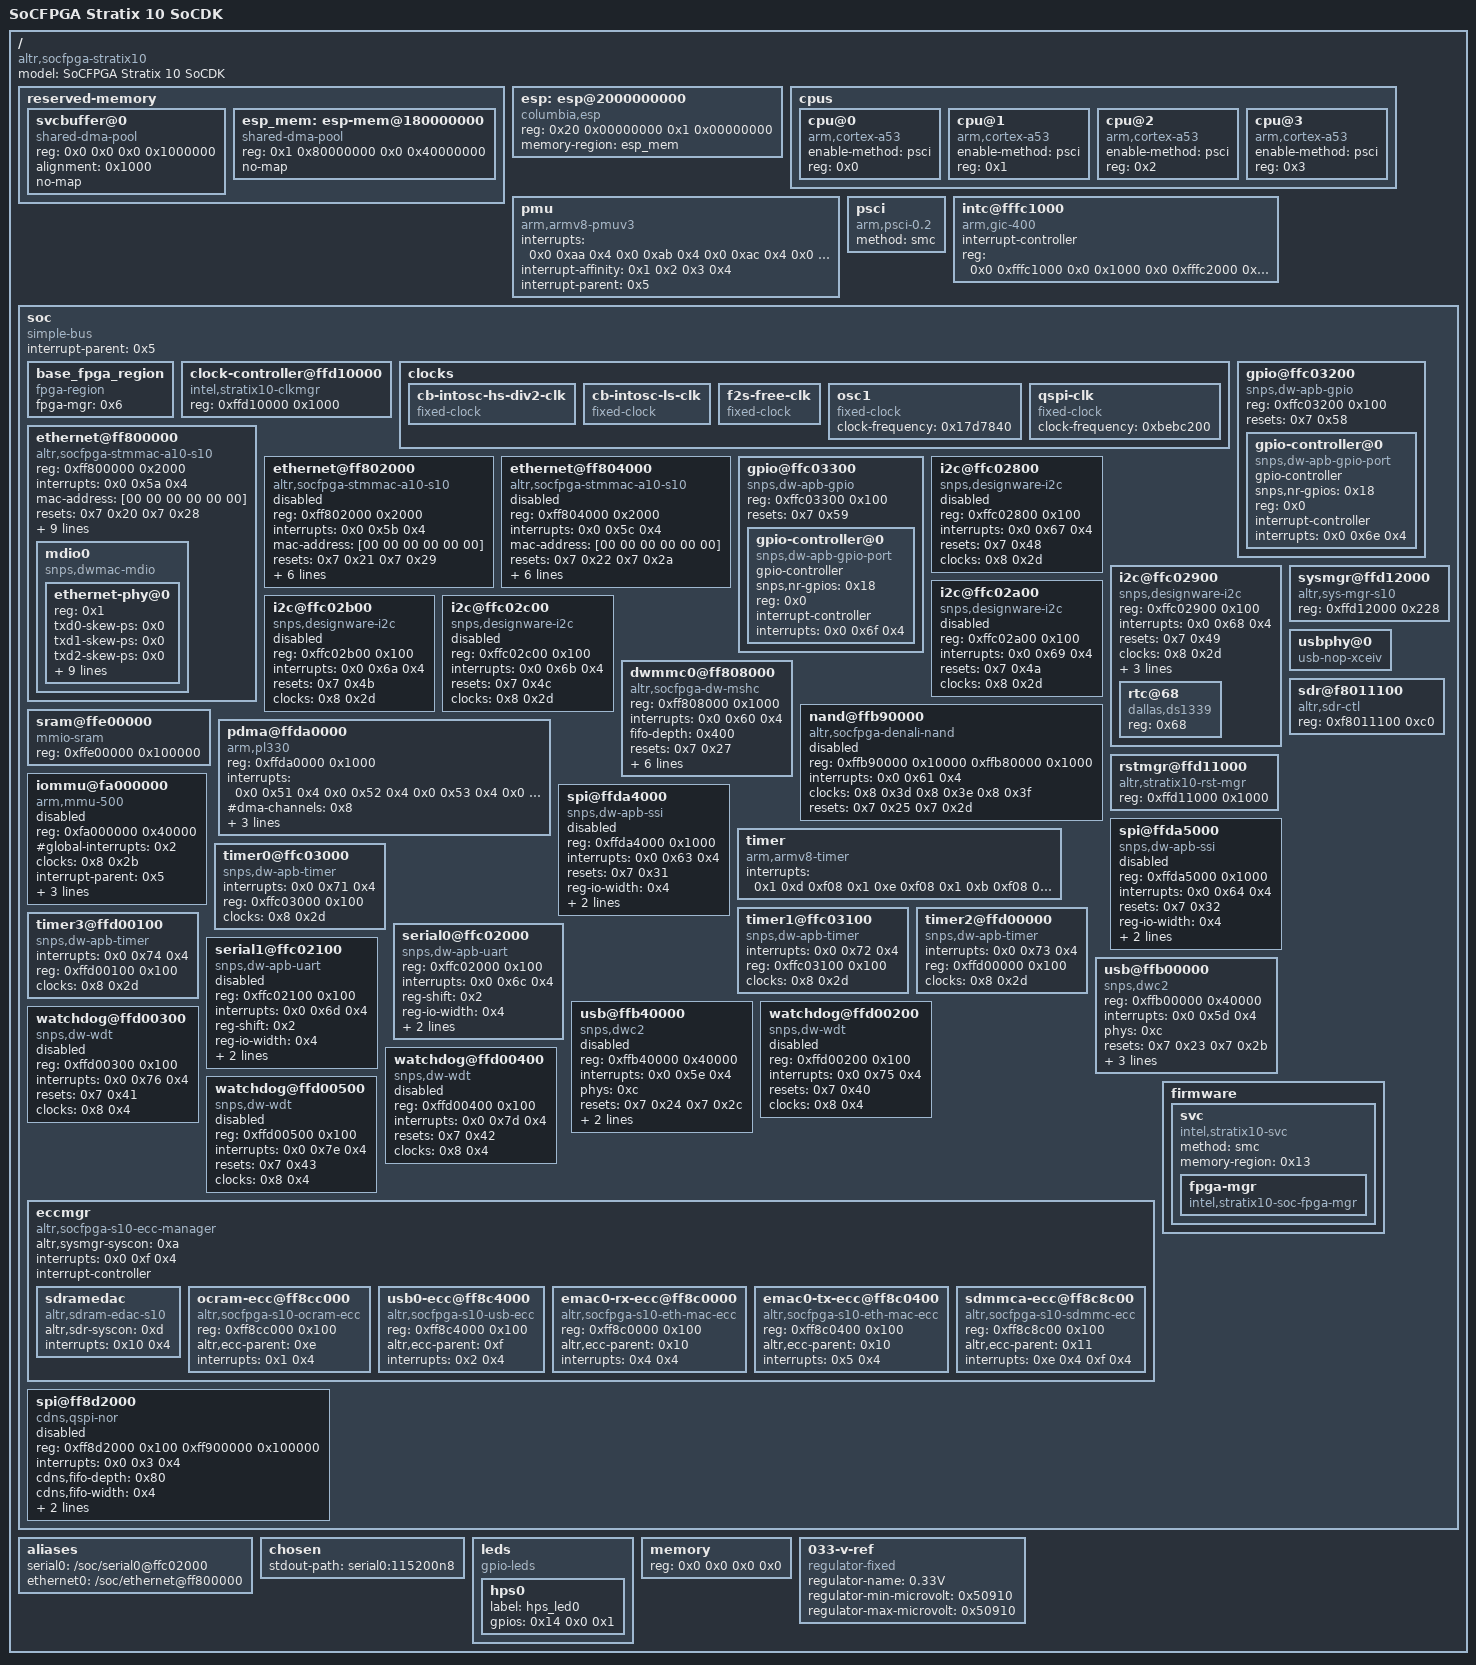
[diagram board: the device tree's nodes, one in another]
/dts-v1/;

/ {
	compatible = "altr,socfpga-stratix10";
	#address-cells = <0x2>;
	#size-cells = <0x2>;
	model = "SoCFPGA Stratix 10 SoCDK";

	reserved-memory {
		#address-cells = <0x2>;
		#size-cells = <0x2>;
		ranges;

		svcbuffer@0 {
			compatible = "shared-dma-pool";
			reg = <0x0 0x0 0x0 0x1000000>;
			alignment = <0x1000>;
			no-map;
			phandle = <0x13>;
		};

		esp_mem: esp-mem@180000000 {
			compatible = "shared-dma-pool";
			reg = <0x1 0x80000000 0x0 0x40000000>; /* 1GB at CPU physical 0x1_8000_0000, matching ESP DRAM aperture */
			no-map;
		};
	};

	esp: esp@2000000000 {
		compatible = "columbia,esp";
		#address-cells = <2>;
		#size-cells = <2>;
		ranges;

		/* Full 4GB H2F MMIO window: 0x20_0000_0000 .. 0x20_FFFF_FFFF */
		reg = <0x20 0x00000000 0x1 0x00000000>;

		memory-region = <&esp_mem>;

		/*
		 * Optional subnodes can mirror the Zynq devicetree if the ESP
		 * driver needs per-region children later.
		 */
	};

	cpus {
		#address-cells = <0x1>;
		#size-cells = <0x0>;

		cpu@0 {
			compatible = "arm,cortex-a53";
			device_type = "cpu";
			enable-method = "psci";
			reg = <0x0>;
			phandle = <0x1>;
		};

		cpu@1 {
			compatible = "arm,cortex-a53";
			device_type = "cpu";
			enable-method = "psci";
			reg = <0x1>;
			phandle = <0x2>;
		};

		cpu@2 {
			compatible = "arm,cortex-a53";
			device_type = "cpu";
			enable-method = "psci";
			reg = <0x2>;
			phandle = <0x3>;
		};

		cpu@3 {
			compatible = "arm,cortex-a53";
			device_type = "cpu";
			enable-method = "psci";
			reg = <0x3>;
			phandle = <0x4>;
		};
	};

	pmu {
		compatible = "arm,armv8-pmuv3";
		interrupts = <0x0 0xaa 0x4 0x0 0xab 0x4 0x0 0xac 0x4 0x0 0xad 0x4>;
		interrupt-affinity = <0x1 0x2 0x3 0x4>;
		interrupt-parent = <0x5>;
	};

	psci {
		compatible = "arm,psci-0.2";
		method = "smc";
	};

	intc@fffc1000 {
		compatible = "arm,gic-400", "arm,cortex-a15-gic";
		#interrupt-cells = <0x3>;
		interrupt-controller;
		reg = <0x0 0xfffc1000 0x0 0x1000 0x0 0xfffc2000 0x0 0x2000 0x0 0xfffc4000 0x0 0x2000 0x0 0xfffc6000 0x0 0x2000>;
		phandle = <0x5>;
	};

	soc {
		#address-cells = <0x1>;
		#size-cells = <0x1>;
		compatible = "simple-bus";
		device_type = "soc";
		interrupt-parent = <0x5>;
		ranges = <0x0 0x0 0x0 0xffffffff>;

		base_fpga_region {
			#address-cells = <0x1>;
			#size-cells = <0x1>;
			compatible = "fpga-region";
			fpga-mgr = <0x6>;
		};

		clock-controller@ffd10000 {
			compatible = "intel,stratix10-clkmgr";
			reg = <0xffd10000 0x1000>;
			#clock-cells = <0x1>;
			phandle = <0x8>;
		};

		clocks {

			cb-intosc-hs-div2-clk {
				#clock-cells = <0x0>;
				compatible = "fixed-clock";
				phandle = <0x15>;
			};

			cb-intosc-ls-clk {
				#clock-cells = <0x0>;
				compatible = "fixed-clock";
				phandle = <0x16>;
			};

			f2s-free-clk {
				#clock-cells = <0x0>;
				compatible = "fixed-clock";
				phandle = <0x17>;
			};

			osc1 {
				#clock-cells = <0x0>;
				compatible = "fixed-clock";
				clock-frequency = <0x17d7840>;
				phandle = <0x18>;
			};

			qspi-clk {
				#clock-cells = <0x0>;
				compatible = "fixed-clock";
				clock-frequency = <0xbebc200>;
				phandle = <0x12>;
			};
		};

		ethernet@ff800000 {
			compatible = "altr,socfpga-stmmac-a10-s10", "snps,dwmac-3.74a", "snps,dwmac";
			reg = <0xff800000 0x2000>;
			interrupts = <0x0 0x5a 0x4>;
			interrupt-names = "macirq";
			mac-address = [00 00 00 00 00 00];
			resets = <0x7 0x20 0x7 0x28>;
			reset-names = "stmmaceth", "stmmaceth-ocp";
			clocks = <0x8 0x34>;
			clock-names = "stmmaceth";
			tx-fifo-depth = <0x4000>;
			rx-fifo-depth = <0x4000>;
			snps,multicast-filter-bins = <0x100>;
			iommus = <0x9 0x1>;
			altr,sysmgr-syscon = <0xa 0x44 0x0>;
			status = "okay";
			phy-mode = "rgmii";
			phy-handle = <0xb>;
			max-frame-size = <0x2328>;
			phandle = <0x10>;

			mdio0 {
				#address-cells = <0x1>;
				#size-cells = <0x0>;
				compatible = "snps,dwmac-mdio";

				ethernet-phy@0 {
					reg = <0x1>;
					txd0-skew-ps = <0x0>;
					txd1-skew-ps = <0x0>;
					txd2-skew-ps = <0x0>;
					txd3-skew-ps = <0x0>;
					rxd0-skew-ps = <0x1a4>;
					rxd1-skew-ps = <0x1a4>;
					rxd2-skew-ps = <0x1a4>;
					rxd3-skew-ps = <0x1a4>;
					txen-skew-ps = <0x0>;
					txc-skew-ps = <0x384>;
					rxdv-skew-ps = <0x1a4>;
					rxc-skew-ps = <0x690>;
					phandle = <0xb>;
				};
			};
		};

		ethernet@ff802000 {
			compatible = "altr,socfpga-stmmac-a10-s10", "snps,dwmac-3.74a", "snps,dwmac";
			reg = <0xff802000 0x2000>;
			interrupts = <0x0 0x5b 0x4>;
			interrupt-names = "macirq";
			mac-address = [00 00 00 00 00 00];
			resets = <0x7 0x21 0x7 0x29>;
			reset-names = "stmmaceth", "stmmaceth-ocp";
			clocks = <0x8 0x35>;
			clock-names = "stmmaceth";
			tx-fifo-depth = <0x4000>;
			rx-fifo-depth = <0x4000>;
			snps,multicast-filter-bins = <0x100>;
			iommus = <0x9 0x2>;
			altr,sysmgr-syscon = <0xa 0x48 0x8>;
			status = "disabled";
			phandle = <0x19>;
		};

		ethernet@ff804000 {
			compatible = "altr,socfpga-stmmac-a10-s10", "snps,dwmac-3.74a", "snps,dwmac";
			reg = <0xff804000 0x2000>;
			interrupts = <0x0 0x5c 0x4>;
			interrupt-names = "macirq";
			mac-address = [00 00 00 00 00 00];
			resets = <0x7 0x22 0x7 0x2a>;
			reset-names = "stmmaceth", "stmmaceth-ocp";
			clocks = <0x8 0x36>;
			clock-names = "stmmaceth";
			tx-fifo-depth = <0x4000>;
			rx-fifo-depth = <0x4000>;
			snps,multicast-filter-bins = <0x100>;
			iommus = <0x9 0x3>;
			altr,sysmgr-syscon = <0xa 0x4c 0x10>;
			status = "disabled";
			phandle = <0x1a>;
		};

		gpio@ffc03200 {
			#address-cells = <0x1>;
			#size-cells = <0x0>;
			compatible = "snps,dw-apb-gpio";
			reg = <0xffc03200 0x100>;
			resets = <0x7 0x58>;
			status = "okay";
			phandle = <0x1b>;

			gpio-controller@0 {
				compatible = "snps,dw-apb-gpio-port";
				gpio-controller;
				#gpio-cells = <0x2>;
				snps,nr-gpios = <0x18>;
				reg = <0x0>;
				interrupt-controller;
				#interrupt-cells = <0x2>;
				interrupts = <0x0 0x6e 0x4>;
				phandle = <0x1c>;
			};
		};

		gpio@ffc03300 {
			#address-cells = <0x1>;
			#size-cells = <0x0>;
			compatible = "snps,dw-apb-gpio";
			reg = <0xffc03300 0x100>;
			resets = <0x7 0x59>;
			status = "okay";
			phandle = <0x1d>;

			gpio-controller@0 {
				compatible = "snps,dw-apb-gpio-port";
				gpio-controller;
				#gpio-cells = <0x2>;
				snps,nr-gpios = <0x18>;
				reg = <0x0>;
				interrupt-controller;
				#interrupt-cells = <0x2>;
				interrupts = <0x0 0x6f 0x4>;
				phandle = <0x14>;
			};
		};

		i2c@ffc02800 {
			#address-cells = <0x1>;
			#size-cells = <0x0>;
			compatible = "snps,designware-i2c";
			reg = <0xffc02800 0x100>;
			interrupts = <0x0 0x67 0x4>;
			resets = <0x7 0x48>;
			clocks = <0x8 0x2d>;
			status = "disabled";
			phandle = <0x1e>;
		};

		i2c@ffc02900 {
			#address-cells = <0x1>;
			#size-cells = <0x0>;
			compatible = "snps,designware-i2c";
			reg = <0xffc02900 0x100>;
			interrupts = <0x0 0x68 0x4>;
			resets = <0x7 0x49>;
			clocks = <0x8 0x2d>;
			status = "okay";
			clock-frequency = <0x186a0>;
			i2c-sda-falling-time-ns = <0x37a>;
			i2c-sdl-falling-time-ns = <0x37a>;
			phandle = <0x1f>;

			rtc@68 {
				compatible = "dallas,ds1339";
				reg = <0x68>;
			};
		};

		i2c@ffc02a00 {
			#address-cells = <0x1>;
			#size-cells = <0x0>;
			compatible = "snps,designware-i2c";
			reg = <0xffc02a00 0x100>;
			interrupts = <0x0 0x69 0x4>;
			resets = <0x7 0x4a>;
			clocks = <0x8 0x2d>;
			status = "disabled";
			phandle = <0x20>;
		};

		i2c@ffc02b00 {
			#address-cells = <0x1>;
			#size-cells = <0x0>;
			compatible = "snps,designware-i2c";
			reg = <0xffc02b00 0x100>;
			interrupts = <0x0 0x6a 0x4>;
			resets = <0x7 0x4b>;
			clocks = <0x8 0x2d>;
			status = "disabled";
			phandle = <0x21>;
		};

		i2c@ffc02c00 {
			#address-cells = <0x1>;
			#size-cells = <0x0>;
			compatible = "snps,designware-i2c";
			reg = <0xffc02c00 0x100>;
			interrupts = <0x0 0x6b 0x4>;
			resets = <0x7 0x4c>;
			clocks = <0x8 0x2d>;
			status = "disabled";
			phandle = <0x22>;
		};

		dwmmc0@ff808000 {
			#address-cells = <0x1>;
			#size-cells = <0x0>;
			compatible = "altr,socfpga-dw-mshc";
			reg = <0xff808000 0x1000>;
			interrupts = <0x0 0x60 0x4>;
			fifo-depth = <0x400>;
			resets = <0x7 0x27>;
			reset-names = "reset";
			clocks = <0x8 0x2c 0x8 0x39>;
			clock-names = "biu", "ciu";
			iommus = <0x9 0x5>;
			status = "okay";
			cap-sd-highspeed;
			cap-mmc-highspeed;
			broken-cd;
			bus-width = <0x4>;
			phandle = <0x11>;
		};

		nand@ffb90000 {
			#address-cells = <0x1>;
			#size-cells = <0x0>;
			compatible = "altr,socfpga-denali-nand";
			reg = <0xffb90000 0x10000 0xffb80000 0x1000>;
			reg-names = "nand_data", "denali_reg";
			interrupts = <0x0 0x61 0x4>;
			clocks = <0x8 0x3d 0x8 0x3e 0x8 0x3f>;
			clock-names = "nand", "nand_x", "ecc";
			resets = <0x7 0x25 0x7 0x2d>;
			status = "disabled";
			phandle = <0x23>;
		};

		sram@ffe00000 {
			compatible = "mmio-sram";
			reg = <0xffe00000 0x100000>;
			phandle = <0xe>;
		};

		pdma@ffda0000 {
			compatible = "arm,pl330", "arm,primecell";
			reg = <0xffda0000 0x1000>;
			interrupts = <0x0 0x51 0x4 0x0 0x52 0x4 0x0 0x53 0x4 0x0 0x54 0x4 0x0 0x55 0x4 0x0 0x56 0x4 0x0 0x57 0x4 0x0 0x58 0x4 0x0 0x59 0x4>;
			#dma-cells = <0x1>;
			#dma-channels = <0x8>;
			#dma-requests = <0x20>;
			clocks = <0x8 0x2b>;
			clock-names = "apb_pclk";
			resets = <0x7 0x30 0x7 0x35>;
			reset-names = "dma", "dma-ocp";
			phandle = <0x24>;
		};

		rstmgr@ffd11000 {
			#reset-cells = <0x1>;
			compatible = "altr,stratix10-rst-mgr";
			reg = <0xffd11000 0x1000>;
			phandle = <0x7>;
		};

		iommu@fa000000 {
			compatible = "arm,mmu-500", "arm,smmu-v2";
			reg = <0xfa000000 0x40000>;
			#global-interrupts = <0x2>;
			#iommu-cells = <0x1>;
			clocks = <0x8 0x2b>;
			clock-names = "iommu";
			interrupt-parent = <0x5>;
			interrupts = <0x0 0x80 0x4 0x0 0x81 0x4 0x0 0x8a 0x4 0x0 0x8b 0x4 0x0 0x8c 0x4 0x0 0x8d 0x4 0x0 0x8e 0x4 0x0 0x8f 0x4 0x0 0x90 0x4 0x0 0x91 0x4 0x0 0x92 0x4 0x0 0x93 0x4 0x0 0x94 0x4 0x0 0x95 0x4 0x0 0x96 0x4 0x0 0x97 0x4 0x0 0x98 0x4 0x0 0x99 0x4 0x0 0x9a 0x4 0x0 0x9b 0x4 0x0 0x9c 0x4 0x0 0x9d 0x4 0x0 0x9e 0x4 0x0 0x9f 0x4 0x0 0xa0 0x4 0x0 0xa1 0x4 0x0 0xa2 0x4 0x0 0xa3 0x4 0x0 0xa4 0x4 0x0 0xa5 0x4 0x0 0xa6 0x4 0x0 0xa7 0x4 0x0 0xa8 0x4 0x0 0xa9 0x4>;
			stream-match-mask = <0x7ff0>;
			status = "disabled";
			phandle = <0x9>;
		};

		spi@ffda4000 {
			compatible = "snps,dw-apb-ssi";
			#address-cells = <0x1>;
			#size-cells = <0x0>;
			reg = <0xffda4000 0x1000>;
			interrupts = <0x0 0x63 0x4>;
			resets = <0x7 0x31>;
			reg-io-width = <0x4>;
			num-cs = <0x4>;
			clocks = <0x8 0x2b>;
			status = "disabled";
			phandle = <0x25>;
		};

		spi@ffda5000 {
			compatible = "snps,dw-apb-ssi";
			#address-cells = <0x1>;
			#size-cells = <0x0>;
			reg = <0xffda5000 0x1000>;
			interrupts = <0x0 0x64 0x4>;
			resets = <0x7 0x32>;
			reg-io-width = <0x4>;
			num-cs = <0x4>;
			clocks = <0x8 0x2b>;
			status = "disabled";
			phandle = <0x26>;
		};

		sysmgr@ffd12000 {
			compatible = "altr,sys-mgr-s10", "altr,sys-mgr";
			reg = <0xffd12000 0x228>;
			phandle = <0xa>;
		};

		timer {
			compatible = "arm,armv8-timer";
			interrupts = <0x1 0xd 0xf08 0x1 0xe 0xf08 0x1 0xb 0xf08 0x1 0xa 0xf08>;
		};

		timer0@ffc03000 {
			compatible = "snps,dw-apb-timer";
			interrupts = <0x0 0x71 0x4>;
			reg = <0xffc03000 0x100>;
			clocks = <0x8 0x2d>;
			clock-names = "timer";
			phandle = <0x27>;
		};

		timer1@ffc03100 {
			compatible = "snps,dw-apb-timer";
			interrupts = <0x0 0x72 0x4>;
			reg = <0xffc03100 0x100>;
			clocks = <0x8 0x2d>;
			clock-names = "timer";
			phandle = <0x28>;
		};

		timer2@ffd00000 {
			compatible = "snps,dw-apb-timer";
			interrupts = <0x0 0x73 0x4>;
			reg = <0xffd00000 0x100>;
			clocks = <0x8 0x2d>;
			clock-names = "timer";
			phandle = <0x29>;
		};

		timer3@ffd00100 {
			compatible = "snps,dw-apb-timer";
			interrupts = <0x0 0x74 0x4>;
			reg = <0xffd00100 0x100>;
			clocks = <0x8 0x2d>;
			clock-names = "timer";
			phandle = <0x2a>;
		};

		serial0@ffc02000 {
			compatible = "snps,dw-apb-uart";
			reg = <0xffc02000 0x100>;
			interrupts = <0x0 0x6c 0x4>;
			reg-shift = <0x2>;
			reg-io-width = <0x4>;
			resets = <0x7 0x50>;
			clocks = <0x8 0x2d>;
			status = "okay";
			phandle = <0x2b>;
		};

		serial1@ffc02100 {
			compatible = "snps,dw-apb-uart";
			reg = <0xffc02100 0x100>;
			interrupts = <0x0 0x6d 0x4>;
			reg-shift = <0x2>;
			reg-io-width = <0x4>;
			resets = <0x7 0x51>;
			clocks = <0x8 0x2d>;
			status = "disabled";
			phandle = <0x2c>;
		};

		usbphy@0 {
			#phy-cells = <0x0>;
			compatible = "usb-nop-xceiv";
			status = "okay";
			phandle = <0xc>;
		};

		usb@ffb00000 {
			compatible = "snps,dwc2";
			reg = <0xffb00000 0x40000>;
			interrupts = <0x0 0x5d 0x4>;
			phys = <0xc>;
			phy-names = "usb2-phy";
			resets = <0x7 0x23 0x7 0x2b>;
			reset-names = "dwc2", "dwc2-ecc";
			clocks = <0x8 0x3b>;
			iommus = <0x9 0x6>;
			status = "okay";
			disable-over-current;
			phandle = <0xf>;
		};

		usb@ffb40000 {
			compatible = "snps,dwc2";
			reg = <0xffb40000 0x40000>;
			interrupts = <0x0 0x5e 0x4>;
			phys = <0xc>;
			phy-names = "usb2-phy";
			resets = <0x7 0x24 0x7 0x2c>;
			reset-names = "dwc2", "dwc2-ecc";
			clocks = <0x8 0x3b>;
			iommus = <0x9 0x7>;
			status = "disabled";
			phandle = <0x2d>;
		};

		watchdog@ffd00200 {
			compatible = "snps,dw-wdt";
			reg = <0xffd00200 0x100>;
			interrupts = <0x0 0x75 0x4>;
			resets = <0x7 0x40>;
			clocks = <0x8 0x4>;
			status = "disabled";
			phandle = <0x2e>;
		};

		watchdog@ffd00300 {
			compatible = "snps,dw-wdt";
			reg = <0xffd00300 0x100>;
			interrupts = <0x0 0x76 0x4>;
			resets = <0x7 0x41>;
			clocks = <0x8 0x4>;
			status = "disabled";
			phandle = <0x2f>;
		};

		watchdog@ffd00400 {
			compatible = "snps,dw-wdt";
			reg = <0xffd00400 0x100>;
			interrupts = <0x0 0x7d 0x4>;
			resets = <0x7 0x42>;
			clocks = <0x8 0x4>;
			status = "disabled";
			phandle = <0x30>;
		};

		watchdog@ffd00500 {
			compatible = "snps,dw-wdt";
			reg = <0xffd00500 0x100>;
			interrupts = <0x0 0x7e 0x4>;
			resets = <0x7 0x43>;
			clocks = <0x8 0x4>;
			status = "disabled";
			phandle = <0x31>;
		};

		sdr@f8011100 {
			compatible = "altr,sdr-ctl", "syscon";
			reg = <0xf8011100 0xc0>;
			phandle = <0xd>;
		};

		eccmgr {
			compatible = "altr,socfpga-s10-ecc-manager", "altr,socfpga-a10-ecc-manager";
			altr,sysmgr-syscon = <0xa>;
			#address-cells = <0x1>;
			#size-cells = <0x1>;
			interrupts = <0x0 0xf 0x4>;
			interrupt-controller;
			#interrupt-cells = <0x2>;
			ranges;

			sdramedac {
				compatible = "altr,sdram-edac-s10";
				altr,sdr-syscon = <0xd>;
				interrupts = <0x10 0x4>;
			};

			ocram-ecc@ff8cc000 {
				compatible = "altr,socfpga-s10-ocram-ecc", "altr,socfpga-a10-ocram-ecc";
				reg = <0xff8cc000 0x100>;
				altr,ecc-parent = <0xe>;
				interrupts = <0x1 0x4>;
			};

			usb0-ecc@ff8c4000 {
				compatible = "altr,socfpga-s10-usb-ecc", "altr,socfpga-usb-ecc";
				reg = <0xff8c4000 0x100>;
				altr,ecc-parent = <0xf>;
				interrupts = <0x2 0x4>;
			};

			emac0-rx-ecc@ff8c0000 {
				compatible = "altr,socfpga-s10-eth-mac-ecc", "altr,socfpga-eth-mac-ecc";
				reg = <0xff8c0000 0x100>;
				altr,ecc-parent = <0x10>;
				interrupts = <0x4 0x4>;
			};

			emac0-tx-ecc@ff8c0400 {
				compatible = "altr,socfpga-s10-eth-mac-ecc", "altr,socfpga-eth-mac-ecc";
				reg = <0xff8c0400 0x100>;
				altr,ecc-parent = <0x10>;
				interrupts = <0x5 0x4>;
			};

			sdmmca-ecc@ff8c8c00 {
				compatible = "altr,socfpga-s10-sdmmc-ecc", "altr,socfpga-sdmmc-ecc";
				reg = <0xff8c8c00 0x100>;
				altr,ecc-parent = <0x11>;
				interrupts = <0xe 0x4 0xf 0x4>;
			};
		};

		spi@ff8d2000 {
			compatible = "cdns,qspi-nor";
			#address-cells = <0x1>;
			#size-cells = <0x0>;
			reg = <0xff8d2000 0x100 0xff900000 0x100000>;
			interrupts = <0x0 0x3 0x4>;
			cdns,fifo-depth = <0x80>;
			cdns,fifo-width = <0x4>;
			cdns,trigger-address = <0x0>;
			clocks = <0x12>;
			status = "disabled";
			phandle = <0x32>;
		};

		firmware {

			svc {
				compatible = "intel,stratix10-svc";
				method = "smc";
				memory-region = <0x13>;

				fpga-mgr {
					compatible = "intel,stratix10-soc-fpga-mgr";
					phandle = <0x6>;
				};
			};
		};
	};

	aliases {
		serial0 = "/soc/serial0@ffc02000";
		ethernet0 = "/soc/ethernet@ff800000";
	};

	chosen {
		stdout-path = "serial0:115200n8";
	};

	leds {
		compatible = "gpio-leds";

		hps0 {
			label = "hps_led0";
			gpios = <0x14 0x0 0x1>;
		};
	};

	memory {
		device_type = "memory";
		reg = <0x0 0x0 0x0 0x0>;
	};

	033-v-ref {
		compatible = "regulator-fixed";
		regulator-name = "0.33V";
		regulator-min-microvolt = <0x50910>;
		regulator-max-microvolt = <0x50910>;
		phandle = <0x33>;
	};

	__symbols__ {
		service_reserved = "/reserved-memory/svcbuffer@0";
		cpu0 = "/cpus/cpu@0";
		cpu1 = "/cpus/cpu@1";
		cpu2 = "/cpus/cpu@2";
		cpu3 = "/cpus/cpu@3";
		intc = "/intc@fffc1000";
		clkmgr = "/soc/clock-controller@ffd10000";
		cb_intosc_hs_div2_clk = "/soc/clocks/cb-intosc-hs-div2-clk";
		cb_intosc_ls_clk = "/soc/clocks/cb-intosc-ls-clk";
		f2s_free_clk = "/soc/clocks/f2s-free-clk";
		osc1 = "/soc/clocks/osc1";
		qspi_clk = "/soc/clocks/qspi-clk";
		gmac0 = "/soc/ethernet@ff800000";
		phy0 = "/soc/ethernet@ff800000/mdio0/ethernet-phy@0";
		gmac1 = "/soc/ethernet@ff802000";
		gmac2 = "/soc/ethernet@ff804000";
		gpio0 = "/soc/gpio@ffc03200";
		porta = "/soc/gpio@ffc03200/gpio-controller@0";
		gpio1 = "/soc/gpio@ffc03300";
		portb = "/soc/gpio@ffc03300/gpio-controller@0";
		i2c0 = "/soc/i2c@ffc02800";
		i2c1 = "/soc/i2c@ffc02900";
		i2c2 = "/soc/i2c@ffc02a00";
		i2c3 = "/soc/i2c@ffc02b00";
		i2c4 = "/soc/i2c@ffc02c00";
		mmc = "/soc/dwmmc0@ff808000";
		nand = "/soc/nand@ffb90000";
		ocram = "/soc/sram@ffe00000";
		pdma = "/soc/pdma@ffda0000";
		rst = "/soc/rstmgr@ffd11000";
		smmu = "/soc/iommu@fa000000";
		spi0 = "/soc/spi@ffda4000";
		spi1 = "/soc/spi@ffda5000";
		sysmgr = "/soc/sysmgr@ffd12000";
		timer0 = "/soc/timer0@ffc03000";
		timer1 = "/soc/timer1@ffc03100";
		timer2 = "/soc/timer2@ffd00000";
		timer3 = "/soc/timer3@ffd00100";
		uart0 = "/soc/serial0@ffc02000";
		uart1 = "/soc/serial1@ffc02100";
		usbphy0 = "/soc/usbphy@0";
		usb0 = "/soc/usb@ffb00000";
		usb1 = "/soc/usb@ffb40000";
		watchdog0 = "/soc/watchdog@ffd00200";
		watchdog1 = "/soc/watchdog@ffd00300";
		watchdog2 = "/soc/watchdog@ffd00400";
		watchdog3 = "/soc/watchdog@ffd00500";
		sdr = "/soc/sdr@f8011100";
		qspi = "/soc/spi@ff8d2000";
		fpga_mgr = "/soc/firmware/svc/fpga-mgr";
		ref_033v = "/033-v-ref";
	};
};
